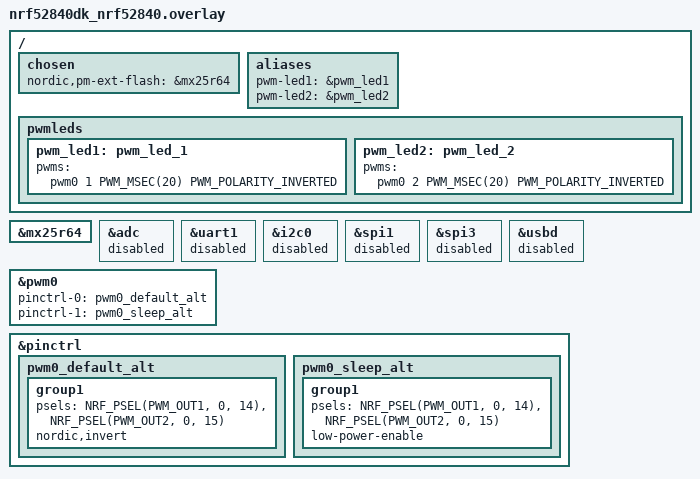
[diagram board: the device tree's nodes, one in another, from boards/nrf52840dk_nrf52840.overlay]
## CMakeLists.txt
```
#
# Copyright (c) 2022 Nordic Semiconductor ASA
#
# SPDX-License-Identifier: LicenseRef-Nordic-5-Clause
#

cmake_minimum_required(VERSION 3.20.0)

include(${CMAKE_CURRENT_LIST_DIR}/../../cmake/find_zephyr.cmake)

project(matter-window-app)

# NORDIC SDK APP START

# Include all source files that are located in the Matter common directory.
include(${ZEPHYR_NCS_MATTER_MODULE_DIR}/cmake/sample.cmake)

ncs_get_zap_parent_dir(ZAP_PARENT_DIR)

target_include_directories(app PRIVATE
  src
  ${ZAP_PARENT_DIR}
)

target_sources(app PRIVATE
  src/app_task.cpp
  src/window_covering.cpp
  src/main.cpp
  src/zcl_callbacks.cpp
)

ncs_configure_data_model()
# NORDIC SDK APP END
```

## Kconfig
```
#
# Copyright (c) 2022 Nordic Semiconductor ASA
#
# SPDX-License-Identifier: LicenseRef-Nordic-5-Clause
#

mainmenu "Matter nRF Connect Window Covering Example Application"

config STATE_LEDS
	bool "Use LEDs to indicate the device state"
	default y
	help
	  Use LEDs to render the current state of the device such as the progress of commissioning of
	  the device into a network or the factory reset initiation. Note that setting this option to
	  'n' does not disable the LED indicating the state of the simulated bolt.

# Reduce Thread TX output power to 0 dBm for SED device
config OPENTHREAD_DEFAULT_TX_POWER
	default 0

choice OPENTHREAD_IMPLEMENTATION
	default OPENTHREAD_SOURCES
endchoice

source "$(ZEPHYR_CONNECTEDHOMEIP_MODULE_DIR)/config/nrfconnect/chip-module/Kconfig.features"
source "$(ZEPHYR_CONNECTEDHOMEIP_MODULE_DIR)/config/nrfconnect/chip-module/Kconfig.defaults"
source "Kconfig.zephyr"
```

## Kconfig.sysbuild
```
#
# Copyright (c) 2023 Nordic Semiconductor ASA
#
# SPDX-License-Identifier: LicenseRef-Nordic-5-Clause
#

#### Radio core selection
config NRF_DEFAULT_IPC_RADIO
	default y

# Enable IEEE802.15.4 serialization to network core
# This config automatically pulls in the `overlay-802154.conf` in the ipc_radio image
config NETCORE_IPC_RADIO_IEEE802154
	default y if SOC_SERIES_NRF53

# Enable Bluetooth serialization to network core
# This config automatically pulls in the `overlay-bt_hci_ipc.conf` in the ipc_radio image
config NETCORE_IPC_RADIO_BT_HCI_IPC
	default y if SOC_SERIES_NRF53

#### Bootloader
choice BOOTLOADER
	default BOOTLOADER_MCUBOOT if !BOARD_NRF21540DK && !BOARD_NATIVE_SIM
endchoice

if BOOTLOADER_MCUBOOT

#### DFU multi-image support
config DFU_MULTI_IMAGE_PACKAGE_BUILD
	default y

config DFU_MULTI_IMAGE_PACKAGE_APP
	default y

#### DFU network core configuration
if SOC_SERIES_NRF53

choice MCUBOOT_MODE
	default MCUBOOT_MODE_OVERWRITE_ONLY
endchoice

choice BOOT_SIGNATURE_TYPE
	default BOOT_SIGNATURE_TYPE_RSA
endchoice

config SECURE_BOOT_NETCORE
	default y

config NETCORE_APP_UPDATE
	default y

config DFU_MULTI_IMAGE_PACKAGE_NET
	default y

endif # SOC_SERIES_NRF53
endif # BOOTLOADER_MCUBOOT

#### Enable generating factory data
config MATTER_ADD_ON_FACTORY_DATA_GENERATE
	default y if !BOARD_NRF21540DK && !BOARD_NATIVE_SIM

source "share/sysbuild/Kconfig"
```

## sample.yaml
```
sample:
  description: Matter Window Covering example
  name: Matter Window Covering
common:
  tags:
    - sysbuild
    - ci_samples_matter
tests:
  sample.matter.window_cover.debug:
    sysbuild: true
    build_only: true
    integration_platforms:
      - nrf5340dk/nrf5340/cpuapp
      - nrf54l15dk/nrf54l15/cpuapp
      - nrf54lm20dk/nrf54lm20b/cpuapp
      - nrf54lm20dk/nrf54lm20a/cpuapp
    platform_allow:
      - nrf5340dk/nrf5340/cpuapp
      - nrf54l15dk/nrf54l15/cpuapp
      - nrf54lm20dk/nrf54lm20b/cpuapp
      - nrf54lm20dk/nrf54lm20a/cpuapp
  sample.matter.window_cover.debug.ssed:
    sysbuild: true
    build_only: true
    extra_args:
      - EXTRA_CONF_FILE=ssed.conf
    integration_platforms:
      - nrf5340dk/nrf5340/cpuapp
      - nrf54l15dk/nrf54l15/cpuapp
      - nrf54lm20dk/nrf54lm20b/cpuapp
      - nrf54lm20dk/nrf54lm20a/cpuapp
    platform_allow:
      - nrf5340dk/nrf5340/cpuapp
      - nrf54l15dk/nrf54l15/cpuapp
      - nrf54lm20dk/nrf54lm20b/cpuapp
      - nrf54lm20dk/nrf54lm20a/cpuapp
  sample.matter.window_cover.release:
    sysbuild: true
    build_only: true
    extra_args:
      - FILE_SUFFIX=release
    integration_platforms:
      - nrf5340dk/nrf5340/cpuapp
      - nrf54l15dk/nrf54l15/cpuapp
      - nrf54lm20dk/nrf54lm20b/cpuapp
      - nrf54lm20dk/nrf54lm20a/cpuapp
    platform_allow:
      - nrf5340dk/nrf5340/cpuapp
      - nrf54l15dk/nrf54l15/cpuapp
      - nrf54lm20dk/nrf54lm20b/cpuapp
      - nrf54lm20dk/nrf54lm20a/cpuapp
  sample.matter.window_cover.release.ssed:
    sysbuild: true
    build_only: true
    extra_args:
      - FILE_SUFFIX=release
      - EXTRA_CONF_FILE=ssed.conf
    integration_platforms:
      - nrf5340dk/nrf5340/cpuapp
      - nrf54l15dk/nrf54l15/cpuapp
      - nrf54lm20dk/nrf54lm20b/cpuapp
      - nrf54lm20dk/nrf54lm20a/cpuapp
    platform_allow:
      - nrf5340dk/nrf5340/cpuapp
      - nrf54l15dk/nrf54l15/cpuapp
      - nrf54lm20dk/nrf54lm20b/cpuapp
      - nrf54lm20dk/nrf54lm20a/cpuapp
  sample.matter.window_cover.release.power_consumption:
    sysbuild: true
    build_only: true
    extra_args:
      - FILE_SUFFIX=release
      - CONFIG_MATTER_LEDS=n
      - CONFIG_MATTER_WATCHDOG=n
      - CONFIG_CHIP_ENABLE_PAIRING_AUTOSTART=y
    integration_platforms:
      - nrf5340dk/nrf5340/cpuapp
      - nrf54l15dk/nrf54l15/cpuapp
      - nrf54lm20dk/nrf54lm20b/cpuapp
      - nrf54lm20dk/nrf54lm20a/cpuapp
    platform_allow:
      - nrf5340dk/nrf5340/cpuapp
      - nrf54l15dk/nrf54l15/cpuapp
      - nrf54lm20dk/nrf54lm20b/cpuapp
      - nrf54lm20dk/nrf54lm20a/cpuapp
  sample.matter.window_cover.release.power_consumption.ssed:
    sysbuild: true
    build_only: true
    extra_args:
      - FILE_SUFFIX=release
      - EXTRA_CONF_FILE=ssed.conf
      - CONFIG_MATTER_LEDS=n
      - CONFIG_MATTER_WATCHDOG=n
      - CONFIG_CHIP_ENABLE_PAIRING_AUTOSTART=y
    integration_platforms:
      - nrf5340dk/nrf5340/cpuapp
      - nrf54l15dk/nrf54l15/cpuapp
      - nrf54lm20dk/nrf54lm20b/cpuapp
      - nrf54lm20dk/nrf54lm20a/cpuapp
    platform_allow:
      - nrf5340dk/nrf5340/cpuapp
      - nrf54l15dk/nrf54l15/cpuapp
      - nrf54lm20dk/nrf54lm20b/cpuapp
      - nrf54lm20dk/nrf54lm20a/cpuapp
  sample.matter.window_cover.smp_dfu:
    sysbuild: true
    build_only: true
    extra_args:
      - CONFIG_CHIP_DFU_OVER_BT_SMP=y
    integration_platforms:
      - nrf5340dk/nrf5340/cpuapp
      - nrf54lm20dk/nrf54lm20b/cpuapp
      - nrf54lm20dk/nrf54lm20a/cpuapp
    platform_allow:
      - nrf5340dk/nrf5340/cpuapp
      - nrf54l15dk/nrf54l15/cpuapp
      - nrf54lm20dk/nrf54lm20b/cpuapp
      - nrf54lm20dk/nrf54lm20a/cpuapp
```

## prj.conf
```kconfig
#
# Copyright (c) 2022 Nordic Semiconductor ASA
#
# SPDX-License-Identifier: LicenseRef-Nordic-5-Clause
#

# This sample uses Kconfig.defaults to set options common for all
# samples. This file should contain only options specific for this sample
# or overrides of default values.

# Enable CHIP
CONFIG_CHIP=y
CONFIG_CHIP_PROJECT_CONFIG="src/chip_project_config.h"
CONFIG_CHIP_DEVICE_PRODUCT_NAME="Matter Window Covering"

# Configure ZAP file name
CONFIG_MATTER_ZAP_FILE_PATH="${APPLICATION_CONFIG_DIR}/src/default_zap/window-app.zap"

# 32784 == 0x8010 (example window-app)
CONFIG_CHIP_DEVICE_PRODUCT_ID=32784
CONFIG_STD_CPP17=y

# Enable Matter pairing automatically on application start.
CONFIG_CHIP_ENABLE_PAIRING_AUTOSTART=y

# Enable Matter extended announcement and increase duration to 1 hour.
CONFIG_CHIP_BLE_EXT_ADVERTISING=y
CONFIG_CHIP_BLE_ADVERTISING_DURATION=60

# Add support for LEDs and buttons on Nordic development kits
CONFIG_DK_LIBRARY=y

# PWM support
CONFIG_PWM=y

# OpenThread configs
CONFIG_OPENTHREAD_NORDIC_LIBRARY_MTD=y
CONFIG_OPENTHREAD_MTD=y
CONFIG_OPENTHREAD_FTD=n
CONFIG_CHIP_ENABLE_ICD_SUPPORT=y
CONFIG_CHIP_ICD_SLOW_POLL_INTERVAL=1000

# Bluetooth Low Energy configuration
CONFIG_BT_DEVICE_NAME="MatterWinCov"

# Suspend devices when the CPU goes into sleep
CONFIG_PM_DEVICE=y

# Stack size settings
CONFIG_IEEE802154_NRF5_RX_STACK_SIZE=1024

# Other settings
CONFIG_THREAD_NAME=y
CONFIG_MPU_STACK_GUARD=y
CONFIG_RESET_ON_FATAL_ERROR=n
CONFIG_CHIP_LIB_SHELL=y
CONFIG_MATTER_TEST_SHELL=y

# Reduce application size
CONFIG_USE_SEGGER_RTT=n

# Enable Factory Data feature
CONFIG_CHIP_FACTORY_DATA=y
CONFIG_CHIP_FACTORY_DATA_BUILD=y
```

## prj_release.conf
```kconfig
#
# Copyright (c) 2022 Nordic Semiconductor ASA
#
# SPDX-License-Identifier: LicenseRef-Nordic-5-Clause
#

# This sample uses Kconfig.defaults to set options common for all
# samples. This file should contain only options specific for this sample
# or overrides of default values.

# Enable CHIP
CONFIG_CHIP=y
CONFIG_CHIP_PROJECT_CONFIG="src/chip_project_config.h"
CONFIG_CHIP_DEVICE_PRODUCT_NAME="Matter Window Covering"

# Configure ZAP file name
CONFIG_MATTER_ZAP_FILE_PATH="${APPLICATION_CONFIG_DIR}/src/default_zap/window-app.zap"

# 32784 == 0x8010 (example window-app)
CONFIG_CHIP_DEVICE_PRODUCT_ID=32784
CONFIG_STD_CPP17=y

# Enable Matter pairing automatically on application start.
CONFIG_CHIP_ENABLE_PAIRING_AUTOSTART=y

# Enable Matter extended announcement and increase duration to 1 hour.
CONFIG_CHIP_BLE_EXT_ADVERTISING=y
CONFIG_CHIP_BLE_ADVERTISING_DURATION=60

# Add support for LEDs and buttons on Nordic development kits
CONFIG_DK_LIBRARY=y

# Try to disable unused RAM blocks to reduce power consumption
CONFIG_RAM_POWER_DOWN_LIBRARY=y

# PWM support
CONFIG_PWM=y

# OpenThread configs
CONFIG_OPENTHREAD_NORDIC_LIBRARY_MTD=y
CONFIG_OPENTHREAD_MTD=y
CONFIG_OPENTHREAD_FTD=n
CONFIG_CHIP_ENABLE_ICD_SUPPORT=y
CONFIG_CHIP_ICD_SLOW_POLL_INTERVAL=1000

# Bluetooth Low Energy configuration
CONFIG_BT_DEVICE_NAME="MatterWinCov"

# Suspend devices when the CPU goes into sleep
CONFIG_PM_DEVICE=y

# Stack size settings
CONFIG_IEEE802154_NRF5_RX_STACK_SIZE=1024

# Enable system reset on fatal error
CONFIG_RESET_ON_FATAL_ERROR=y

# Disable all debug features
CONFIG_USE_SEGGER_RTT=n
CONFIG_SHELL=n
CONFIG_OPENTHREAD_SHELL=n
CONFIG_CONSOLE=n
CONFIG_UART_CONSOLE=n
CONFIG_SERIAL=n
CONFIG_LOG=n
CONFIG_LOG_MODE_MINIMAL=n
CONFIG_ASSERT_VERBOSE=n
CONFIG_ASSERT_NO_FILE_INFO=y
CONFIG_PRINTK=n
CONFIG_PRINTK_SYNC=n
CONFIG_THREAD_NAME=n
CONFIG_BOOT_BANNER=n

# Enable Factory Data feature
CONFIG_CHIP_FACTORY_DATA=y
CONFIG_CHIP_FACTORY_DATA_BUILD=y

# Enable Watchdog
CONFIG_MATTER_WATCHDOG=y

# Enable LTO to decrease the flash usage.
CONFIG_LTO=y
CONFIG_ISR_TABLES_LOCAL_DECLARATION=y
```

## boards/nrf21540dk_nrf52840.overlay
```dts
/* Copyright (c) 2021 Nordic Semiconductor ASA
 *
 * SPDX-License-Identifier: LicenseRef-Nordic-5-Clause
 */

#include <nrf52840_partitions.dtsi>

/ {
	/*
	 * Configure LED2 and LED3 to show the state of the
	 * window cover,by using the LED's brightness level.
	 */
	aliases {
		pwm-led1 = &pwm_led1;
		pwm-led2 = &pwm_led2;
	};

	pwmleds {
		pwm_led1: pwm_led_1 {
			pwms = <&pwm0 1 PWM_MSEC(20) PWM_POLARITY_INVERTED>;
		};

		pwm_led2: pwm_led_2 {
			pwms = <&pwm0 2 PWM_MSEC(20) PWM_POLARITY_INVERTED>;
		};
	};
};

/* Disable unused peripherals to reduce power consumption */
&adc {
	status = "disabled";
};

&uart1 {
	status = "disabled";
};

&i2c0 {
	status = "disabled";
};

&spi1 {
	status = "disabled";
};

&spi3 {
	status = "disabled";
};

&usbd {
	status = "disabled";
};

&pwm0 {
	pinctrl-0 = <&pwm0_default_alt>;
	pinctrl-1 = <&pwm0_sleep_alt>;
	pinctrl-names = "default", "sleep";
};

&pinctrl {
	pwm0_default_alt: pwm0_default_alt {
		group1 {
			psels = <NRF_PSEL(PWM_OUT1, 0, 14)>, <NRF_PSEL(PWM_OUT2, 0, 15)>;
			nordic,invert;
		};
	};

	pwm0_sleep_alt: pwm0_sleep_alt {
		group1 {
			psels = <NRF_PSEL(PWM_OUT1, 0, 14)>, <NRF_PSEL(PWM_OUT2, 0, 15)>;
			low-power-enable;
		};
	};
};
```

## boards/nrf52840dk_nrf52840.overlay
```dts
/*
 * Copyright (c) 2021 Nordic Semiconductor ASA
 *
 * SPDX-License-Identifier: LicenseRef-Nordic-5-Clause
 */

#include <nrf52840_partitions.dtsi>

/ {
	chosen {
		nordic,pm-ext-flash = &mx25r64;
	};

	/*
	 * Configure LED2 and LED3 to show the state of the
	 * window cover,by using the LED's brightness level.
	 */
	aliases {
		pwm-led1 = &pwm_led1;
		pwm-led2 = &pwm_led2;
	};

	pwmleds {
		pwm_led1: pwm_led_1 {
			pwms = <&pwm0 1 PWM_MSEC(20) PWM_POLARITY_INVERTED>;
		};

		pwm_led2: pwm_led_2 {
			pwms = <&pwm0 2 PWM_MSEC(20) PWM_POLARITY_INVERTED>;
		};
	};
};

&mx25r64 {
	status = "okay";
};

/* Disable unused peripherals to reduce power consumption */
&adc {
	status = "disabled";
};

&uart1 {
	status = "disabled";
};

&i2c0 {
	status = "disabled";
};

&spi1 {
	status = "disabled";
};

&spi3 {
	status = "disabled";
};

&usbd {
	status = "disabled";
};

&pwm0 {
	pinctrl-0 = <&pwm0_default_alt>;
	pinctrl-1 = <&pwm0_sleep_alt>;
	pinctrl-names = "default", "sleep";
};

&pinctrl {
	pwm0_default_alt: pwm0_default_alt {
		group1 {
			psels = <NRF_PSEL(PWM_OUT1, 0, 14)>, <NRF_PSEL(PWM_OUT2, 0, 15)>;
			nordic,invert;
		};
	};

	pwm0_sleep_alt: pwm0_sleep_alt {
		group1 {
			psels = <NRF_PSEL(PWM_OUT1, 0, 14)>, <NRF_PSEL(PWM_OUT2, 0, 15)>;
			low-power-enable;
		};
	};
};
```

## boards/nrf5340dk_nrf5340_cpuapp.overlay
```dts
/*
 * Copyright (c) 2021 Nordic Semiconductor ASA
 *
 * SPDX-License-Identifier: LicenseRef-Nordic-5-Clause
 */

#include <nrf5340_cpuapp_partitions.dtsi>
#include <zephyr/dt-bindings/ipc_service/static_vrings.h>

/ {
	chosen {
		nordic,pm-ext-flash = &mx25r64;
	};

	/*
	 * Configure LED2 and LED3 to show the state of the
	 * window cover,by using the LED's brightness level.
	 */
	aliases {
		pwm-led1 = &pwm_led1;
		pwm-led2 = &pwm_led2;
	};

	pwmleds {
		compatible = "pwm-leds";

		pwm_led1: pwm_led_1 {
			pwms = <&pwm0 1 PWM_MSEC(20) PWM_POLARITY_INVERTED>;
		};

		pwm_led2: pwm_led_2 {
			pwms = <&pwm0 2 PWM_MSEC(20) PWM_POLARITY_INVERTED>;
		};
	};
};

&mx25r64 {
	status = "okay";
};

/* Set IPC thread priority to the highest value to not collide with other threads. */
&ipc0 {
	zephyr,priority = <0 PRIO_COOP>;
};

/* Disable unused peripherals to reduce power consumption */
&adc {
	status = "disabled";
};

&i2c1 {
	status = "disabled";
};

&spi2 {
	status = "disabled";
};

&usbd {
	status = "disabled";
};

&pwm0 {
	pinctrl-0 = <&pwm0_default_alt>;
	pinctrl-1 = <&pwm0_sleep_alt>;
	pinctrl-names = "default", "sleep";
};

&pinctrl {
	pwm0_default_alt: pwm0_default_alt {
		group1 {
			psels = <NRF_PSEL(PWM_OUT1, 0, 29)>, <NRF_PSEL(PWM_OUT2, 0, 30)>;
			nordic,invert;
		};
	};

	pwm0_sleep_alt: pwm0_sleep_alt {
		group1 {
			psels = <NRF_PSEL(PWM_OUT1, 0, 29)>, <NRF_PSEL(PWM_OUT2, 0, 30)>;
			low-power-enable;
		};
	};
};
```

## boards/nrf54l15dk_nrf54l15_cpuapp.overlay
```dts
/*
 * Copyright (c) 2024 Nordic Semiconductor ASA
 *
 * SPDX-License-Identifier: LicenseRef-Nordic-5-Clause
 */

#include <nrf54l15_cpuapp_partitions.dtsi>

/ {
	chosen {
		nordic,pm-ext-flash = &mx25r64;
	};

	aliases {
		/* Configure PWM module for led1 (LED2 on the board) */
		pwm-led1 = &pwm_led1;
		pwm-led2 = &pwm_led2;

		/* Use watchdog wdt31 as the application watchdog */
		watchdog0 = &wdt31;
	};

	pwmleds {
		compatible = "pwm-leds";

		pwm_led1: pwm_led_1 {
			pwms = <&pwm20 1 PWM_MSEC(20) PWM_POLARITY_NORMAL>;
		};

		pwm_led2: pwm_led_2 {
			pwms = <&pwm20 2 PWM_MSEC(20) PWM_POLARITY_NORMAL>;
		};
	};
};

&mx25r64 {
	status = "okay";
};

&pwm20 {
	status = "okay";
	pinctrl-0 = <&pwm_default>;
	pinctrl-1 = <&pwm_sleep>;
	pinctrl-names = "default", "sleep";
};

&pinctrl {
	pwm_default: pwm_default {
		group1 {
			psels = <NRF_PSEL(PWM_OUT1, 1, 10)>, <NRF_PSEL(PWM_OUT2, 1, 14)>;
		};
	};

	pwm_sleep: pwm_sleep {
		group1 {
			psels = <NRF_PSEL(PWM_OUT1, 1, 10)>, <NRF_PSEL(PWM_OUT2, 1, 14)>;
			low-power-enable;
		};
	};
};

&wdt31 {
	status = "okay";
};
```

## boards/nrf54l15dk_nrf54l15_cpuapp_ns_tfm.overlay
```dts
/*
 * Copyright (c) 2026 Nordic Semiconductor ASA
 *
 * SPDX-License-Identifier: LicenseRef-Nordic-5-Clause
 */

#include <nrf54l15_cpuapp_tfm_application_partitions.dtsi>

/ {
	chosen {
		nordic,pm-ext-flash = &mx25r64;
	};

	aliases {
		/* Configure PWM module for led1 (LED2 on the board) */
		pwm-led1 = &pwm_led1;
		pwm-led2 = &pwm_led2;

		/* Use watchdog wdt31 as the application watchdog */
		watchdog0 = &wdt31;
	};

	pwmleds {
		compatible = "pwm-leds";

		pwm_led1: pwm_led_1 {
			pwms = <&pwm20 1 PWM_MSEC(20) PWM_POLARITY_NORMAL>;
		};

		pwm_led2: pwm_led_2 {
			pwms = <&pwm20 2 PWM_MSEC(20) PWM_POLARITY_NORMAL>;
		};
	};
};

&mx25r64 {
	status = "okay";
};

&pwm20 {
	status = "okay";
	pinctrl-0 = <&pwm_default>;
	pinctrl-1 = <&pwm_sleep>;
	pinctrl-names = "default", "sleep";
};

&pinctrl {
	pwm_default: pwm_default {
		group1 {
			psels = <NRF_PSEL(PWM_OUT1, 1, 10)>, <NRF_PSEL(PWM_OUT2, 1, 14)>;
		};
	};

	pwm_sleep: pwm_sleep {
		group1 {
			psels = <NRF_PSEL(PWM_OUT1, 1, 10)>, <NRF_PSEL(PWM_OUT2, 1, 14)>;
			low-power-enable;
		};
	};
};

&wdt31 {
	status = "okay";
};

/* Change IRQ ids to handle button interrupts.
 * The default values for nRF54L15 are 219 and 269,
 * but with TF-M they are reserved for the secure domain
 * (218 and 268 are reserved for the non-secure domain).
 */
&gpiote20 {
	interrupts = <218 NRF_DEFAULT_IRQ_PRIORITY>;
};

&gpiote30 {
	interrupts = <268 NRF_DEFAULT_IRQ_PRIORITY>;
};
```

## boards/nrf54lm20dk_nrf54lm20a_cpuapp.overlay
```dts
/*
 * Copyright (c) 2025 Nordic Semiconductor ASA
 *
 * SPDX-License-Identifier: LicenseRef-Nordic-5-Clause
 */

#include <nrf54lm20_cpuapp_partitions.dtsi>

/ {
	chosen {
		nordic,pm-ext-flash = &mx25r64;
	};

	aliases {
		pwm-led1 = &pwm_led1;
		pwm-led2 = &pwm_led2;

		/* Use watchdog wdt31 as the application watchdog */
		watchdog0 = &wdt31;
	};

	pwmleds {
		compatible = "pwm-leds";

		pwm_led1: pwm_led_1 {
			pwms = <&pwm20 1 PWM_MSEC(20) PWM_POLARITY_NORMAL>;
		};

		pwm_led2: pwm_led_2 {
			pwms = <&pwm20 2 PWM_MSEC(20) PWM_POLARITY_NORMAL>;
		};
	};
};

&pwm20 {
	status = "okay";
	pinctrl-0 = <&pwm_default>;
	pinctrl-1 = <&pwm_sleep>;
	pinctrl-names = "default", "sleep";
};

&pinctrl {
	pwm_default: pwm_default {
		group1 {
			psels = <NRF_PSEL(PWM_OUT1, 1, 25)>, <NRF_PSEL(PWM_OUT2, 1, 27)>;
		};
	};

	pwm_sleep: pwm_sleep {
		group1 {
			psels = <NRF_PSEL(PWM_OUT1, 1, 25)>, <NRF_PSEL(PWM_OUT2, 1, 27)>;
			low-power-enable;
		};
	};
};

&mx25r64 {
	status = "okay";
};

&wdt31 {
	status = "okay";
};
```

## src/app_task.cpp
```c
/*
 * Copyright (c) 2022 Nordic Semiconductor ASA
 *
 * SPDX-License-Identifier: LicenseRef-Nordic-5-Clause
 */

#include "app_task.h"

#include "window_covering.h"

#include "app/matter_init.h"
#include "app/task_executor.h"
#include "clusters/identify.h"

#include <setup_payload/OnboardingCodesUtil.h>

#include <zephyr/logging/log.h>

LOG_MODULE_DECLARE(app, CONFIG_CHIP_APP_LOG_LEVEL);

using namespace ::chip;
using namespace ::chip::app;
using namespace ::chip::DeviceLayer;

namespace
{
Nrf::Matter::IdentifyCluster sIdentifyCluster(WindowCovering::Endpoint());

#ifdef CONFIG_DK_LIBRARY
#define OPEN_BUTTON_MASK DK_BTN2_MSK
#define CLOSE_BUTTON_MASK DK_BTN3_MSK
#else
#define OPEN_BUTTON_MASK 0
#define CLOSE_BUTTON_MASK 0
#endif
} /* namespace */

void AppTask::ButtonEventHandler(Nrf::ButtonState state, Nrf::ButtonMask hasChanged)
{
	if (OPEN_BUTTON_MASK & hasChanged) {
		WindowButtonAction action =
			(OPEN_BUTTON_MASK & state) ? WindowButtonAction::Pressed : WindowButtonAction::Released;
		Nrf::PostTask([action] { OpenHandler(action); });
	}

	if (CLOSE_BUTTON_MASK & hasChanged) {
		WindowButtonAction action =
			(CLOSE_BUTTON_MASK & state) ? WindowButtonAction::Pressed : WindowButtonAction::Released;
		Nrf::PostTask([action] { CloseHandler(action); });
	}
}

void AppTask::OpenHandler(const WindowButtonAction &action)
{
	if (action == WindowButtonAction::Pressed) {
		Instance().mOpenButtonIsPressed = true;
		if (Instance().mCloseButtonIsPressed) {
			Instance().ToggleMoveType();
		}
	} else {
		if (!Instance().mCloseButtonIsPressed) {
			if (!Instance().mMoveTypeRecentlyChanged) {
				WindowCovering::Instance().SetSingleStepTarget(OperationalState::MovingUpOrOpen);
			} else {
				Instance().mMoveTypeRecentlyChanged = false;
			}
		}
		Instance().mOpenButtonIsPressed = false;
	}
}

void AppTask::CloseHandler(const WindowButtonAction &action)
{
	if (action == WindowButtonAction::Pressed) {
		Instance().mCloseButtonIsPressed = true;
		if (Instance().mOpenButtonIsPressed) {
			Instance().ToggleMoveType();
		}
	} else {
		if (!Instance().mOpenButtonIsPressed) {
			if (!Instance().mMoveTypeRecentlyChanged) {
				WindowCovering::Instance().SetSingleStepTarget(OperationalState::MovingDownOrClose);
			} else {
				Instance().mMoveTypeRecentlyChanged = false;
			}
		}
		Instance().mCloseButtonIsPressed = false;
	}
}

void AppTask::ToggleMoveType()
{
	if (WindowCovering::Instance().GetMoveType() == WindowCovering::MoveType::LIFT) {
		WindowCovering::Instance().SetMoveType(WindowCovering::MoveType::TILT);
		LOG_INF("Window covering move: tilt");
	} else {
		WindowCovering::Instance().SetMoveType(WindowCovering::MoveType::LIFT);
		LOG_INF("Window covering move: lift");
	}
	mMoveTypeRecentlyChanged = true;
}

CHIP_ERROR AppTask::Init()
{
	/* Initialize Matter stack */
	ReturnErrorOnFailure(Nrf::Matter::PrepareServer(Nrf::Matter::InitData{ .mPostServerInitClbk = [] {
		WindowCovering::Instance().PositionLEDUpdate(WindowCovering::MoveType::LIFT);
		WindowCovering::Instance().PositionLEDUpdate(WindowCovering::MoveType::TILT);
		return CHIP_NO_ERROR;
	} }));

	if (!Nrf::GetBoard().Init(ButtonEventHandler)) {
		LOG_ERR("User interface initialization failed.");
		return CHIP_ERROR_INCORRECT_STATE;
	}

	/* Register Matter event handler that controls the connectivity status LED based on the captured Matter network
	 * state. */
	ReturnErrorOnFailure(Nrf::Matter::RegisterEventHandler(Nrf::Board::DefaultMatterEventHandler, 0));

	return Nrf::Matter::StartServer();
}

CHIP_ERROR AppTask::StartApp()
{
	ReturnErrorOnFailure(Init());

	while (true) {
		Nrf::DispatchNextTask();
	}

	return CHIP_NO_ERROR;
}
```

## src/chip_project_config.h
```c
/*
 * Copyright (c) 2022 Nordic Semiconductor ASA
 *
 * SPDX-License-Identifier: LicenseRef-Nordic-5-Clause
 */

/**
 *    @file
 *          Example project configuration file for CHIP.
 *
 *          This is a place to put application or project-specific overrides
 *          to the default configuration values for general CHIP features.
 *
 */

#pragma once

#include "../../../subsys/app/chip_project_config_native_sim.h"
```

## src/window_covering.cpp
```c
/*
 * Copyright (c) 2022 Nordic Semiconductor ASA
 *
 * SPDX-License-Identifier: LicenseRef-Nordic-5-Clause
 */

#include "window_covering.h"

#if defined(CONFIG_PWM)
#include "pwm/pwm_device.h"
#endif

#include <app-common/zap-generated/attributes/Accessors.h>
#include <lib/support/logging/CHIPLogging.h>
#include <platform/CHIPDeviceLayer.h>
#include <zephyr/kernel.h>
#include <zephyr/logging/log.h>

LOG_MODULE_DECLARE(app, CONFIG_CHIP_APP_LOG_LEVEL);

using namespace ::chip;
using namespace ::chip::DeviceLayer;
using namespace chip::app::Clusters::WindowCovering;

#if defined(CONFIG_PWM)
static const struct pwm_dt_spec sLiftPwmDevice = PWM_DT_SPEC_GET(DT_ALIAS(pwm_led1));
static const struct pwm_dt_spec sTiltPwmDevice = PWM_DT_SPEC_GET(DT_ALIAS(pwm_led2));
#endif

static constexpr uint32_t sMoveTimeoutMs{ 200 };

WindowCovering::WindowCovering()
{
#if defined(CONFIG_PWM)
	if (mLiftIndicator.Init(&sLiftPwmDevice, 0, 255) != 0) {
		LOG_ERR("Cannot initialize the lift indicator");
	}
	if (mTiltIndicator.Init(&sTiltPwmDevice, 0, 255) != 0) {
		LOG_ERR("Cannot initialize the tilt indicator");
	}
#endif
}

void WindowCovering::DriveCurrentLiftPosition(intptr_t)
{
	NPercent100ths current{};
	NPercent100ths target{};
	NPercent100ths positionToSet{};

	VerifyOrReturn(Attributes::CurrentPositionLiftPercent100ths::Get(Endpoint(), current) ==
		       Protocols::InteractionModel::Status::Success);
	VerifyOrReturn(Attributes::TargetPositionLiftPercent100ths::Get(Endpoint(), target) ==
		       Protocols::InteractionModel::Status::Success);

	OperationalState state = ComputeOperationalState(target, current);
	UpdateOperationalStatus(MoveType::LIFT, state);

	chip::Percent100ths position = CalculateNextPosition(MoveType::LIFT);

	if (state == OperationalState::MovingUpOrOpen) {
		positionToSet.SetNonNull(position > target.Value() ? position : target.Value());
	} else if (state == OperationalState::MovingDownOrClose) {
		positionToSet.SetNonNull(position < target.Value() ? position : target.Value());
	} else {
		positionToSet.SetNonNull(current.Value());
	}

	LiftPositionSet(Endpoint(), positionToSet);

	/* assume single move completed */
	Instance().mInLiftMove = false;

	VerifyOrReturn(Attributes::CurrentPositionLiftPercent100ths::Get(Endpoint(), current) ==
		       Protocols::InteractionModel::Status::Success);

	if (!TargetCompleted(MoveType::LIFT, current, target)) {
		/* continue to move */
		StartTimer(MoveType::LIFT, sMoveTimeoutMs);
	} else {
		/* the OperationalStatus should indicate no-lift-movement after the target is completed */
		UpdateOperationalStatus(MoveType::LIFT, ComputeOperationalState(target, current));
	}
}

chip::Percent100ths WindowCovering::CalculateNextPosition(MoveType aMoveType)
{
	Protocols::InteractionModel::Status status{};
	chip::Percent100ths percent100ths{};
	NPercent100ths current{};
	OperationalState opState{};

	if (aMoveType == MoveType::LIFT) {
		status = Attributes::CurrentPositionLiftPercent100ths::Get(Endpoint(), current);
		opState = OperationalStateGet(Endpoint(), OperationalStatus::kLift);
	} else if (aMoveType == MoveType::TILT) {
		status = Attributes::CurrentPositionTiltPercent100ths::Get(Endpoint(), current);
		opState = OperationalStateGet(Endpoint(), OperationalStatus::kTilt);
	}

	if ((status == Protocols::InteractionModel::Status::Success) && !current.IsNull()) {
		static constexpr auto sPercentDelta{ WC_PERCENT100THS_MAX_CLOSED / 20 };
		percent100ths = ComputePercent100thsStep(opState, current.Value(), sPercentDelta);
	} else {
		LOG_ERR("Cannot read the current lift position. Error: %d", static_cast<uint8_t>(status));
	}

	return percent100ths;
}

bool WindowCovering::TargetCompleted(MoveType aMoveType, NPercent100ths aCurrent, NPercent100ths aTarget)
{
	return (OperationalState::Stall == ComputeOperationalState(aTarget, aCurrent));
}

void WindowCovering::StartTimer(MoveType aMoveType, uint32_t aTimeoutMs)
{
	MoveType *moveType = chip::Platform::New<MoveType>();
	VerifyOrReturn(moveType != nullptr);

	*moveType = aMoveType;
	(void)chip::DeviceLayer::SystemLayer().StartTimer(chip::System::Clock::Milliseconds32(aTimeoutMs),
							  MoveTimerTimeoutCallback, reinterpret_cast<void *>(moveType));
}

void WindowCovering::MoveTimerTimeoutCallback(chip::System::Layer *systemLayer, void *appState)
{
	MoveType *moveType = reinterpret_cast<MoveType *>(appState);
	VerifyOrReturn(moveType != nullptr);

	if (*moveType == MoveType::LIFT) {
		CHIP_ERROR err = chip::DeviceLayer::PlatformMgr().ScheduleWork(WindowCovering::DriveCurrentLiftPosition);
		if (err != CHIP_NO_ERROR) {
			ChipLogError(NotSpecified, "ScheduleWork failed: %" CHIP_ERROR_FORMAT, err.Format());
		}
	} else if (*moveType == MoveType::TILT) {
		CHIP_ERROR err = chip::DeviceLayer::PlatformMgr().ScheduleWork(WindowCovering::DriveCurrentTiltPosition);
		if (err != CHIP_NO_ERROR) {
			ChipLogError(NotSpecified, "ScheduleWork failed: %" CHIP_ERROR_FORMAT, err.Format());
		}
	}

	chip::Platform::Delete(moveType);
}

void WindowCovering::DriveCurrentTiltPosition(intptr_t)
{
	NPercent100ths current{};
	NPercent100ths target{};
	NPercent100ths positionToSet{};

	VerifyOrReturn(Attributes::CurrentPositionTiltPercent100ths::Get(Endpoint(), current) ==
		       Protocols::InteractionModel::Status::Success);
	VerifyOrReturn(Attributes::TargetPositionTiltPercent100ths::Get(Endpoint(), target) ==
		       Protocols::InteractionModel::Status::Success);

	OperationalState state = ComputeOperationalState(target, current);
	UpdateOperationalStatus(MoveType::TILT, state);

	chip::Percent100ths position = CalculateNextPosition(MoveType::TILT);

	if (state == OperationalState::MovingUpOrOpen) {
		positionToSet.SetNonNull(position > target.Value() ? position : target.Value());
	} else if (state == OperationalState::MovingDownOrClose) {
		positionToSet.SetNonNull(position < target.Value() ? position : target.Value());
	} else {
		positionToSet.SetNonNull(current.Value());
	}

	TiltPositionSet(Endpoint(), positionToSet);

	/* assume single move completed */
	Instance().mInTiltMove = false;

	VerifyOrReturn(Attributes::CurrentPositionTiltPercent100ths::Get(Endpoint(), current) ==
		       Protocols::InteractionModel::Status::Success);

	if (!TargetCompleted(MoveType::TILT, current, target)) {
		/* continue to move */
		StartTimer(MoveType::TILT, sMoveTimeoutMs);
	} else {
		/* the OperationalStatus should indicate no-tilt-movement after the target is completed */
		UpdateOperationalStatus(MoveType::TILT, ComputeOperationalState(target, current));
	}
}

void WindowCovering::StartMove(MoveType aMoveType)
{
	switch (aMoveType) {
	case MoveType::LIFT:
		if (!mInLiftMove) {
			mInLiftMove = true;
			StartTimer(aMoveType, sMoveTimeoutMs);
		}
		break;
	case MoveType::TILT:
		if (!mInTiltMove) {
			mInTiltMove = true;
			StartTimer(aMoveType, sMoveTimeoutMs);
		}
		break;
	default:
		break;
	};
}

void WindowCovering::SetSingleStepTarget(OperationalState aDirection)
{
	UpdateOperationalStatus(mCurrentUIMoveType, aDirection);
	SetTargetPosition(aDirection, CalculateNextPosition(mCurrentUIMoveType));
}

void WindowCovering::UpdateOperationalStatus(MoveType aMoveType, OperationalState aDirection)
{
	switch (aMoveType) {
	case MoveType::LIFT:
		OperationalStateSet(Endpoint(), OperationalStatus::kLift, aDirection);
		break;
	case MoveType::TILT:
		OperationalStateSet(Endpoint(), OperationalStatus::kTilt, aDirection);
		break;
	case MoveType::NONE:
		break;
	default:
		break;
	}
}

void WindowCovering::SetTargetPosition(OperationalState aDirection, chip::Percent100ths aPosition)
{
	Protocols::InteractionModel::Status status{};
	if (Instance().mCurrentUIMoveType == MoveType::LIFT) {
		status = Attributes::TargetPositionLiftPercent100ths::Set(Endpoint(), aPosition);
	} else if (Instance().mCurrentUIMoveType == MoveType::TILT) {
		status = Attributes::TargetPositionTiltPercent100ths::Set(Endpoint(), aPosition);
	}

	if (status != Protocols::InteractionModel::Status::Success) {
		LOG_ERR("Cannot set the target position. Error: %d", static_cast<uint8_t>(status));
	}
}

void WindowCovering::PositionLEDUpdate(MoveType aMoveType)
{
	Protocols::InteractionModel::Status status{};
	NPercent100ths currentPosition{};

	if (aMoveType == MoveType::LIFT) {
		status = Attributes::CurrentPositionLiftPercent100ths::Get(Endpoint(), currentPosition);
		if (Protocols::InteractionModel::Status::Success == status && !currentPosition.IsNull()) {
			Instance().SetBrightness(MoveType::LIFT, currentPosition.Value());
		}
	} else if (aMoveType == MoveType::TILT) {
		status = Attributes::CurrentPositionTiltPercent100ths::Get(Endpoint(), currentPosition);
		if (Protocols::InteractionModel::Status::Success == status && !currentPosition.IsNull()) {
			Instance().SetBrightness(MoveType::TILT, currentPosition.Value());
		}
	}
}

void WindowCovering::SetBrightness(MoveType aMoveType, uint16_t aPosition)
{
#if defined(CONFIG_PWM)
	uint8_t brightness = PositionToBrightness(aPosition, aMoveType);
	if (aMoveType == MoveType::LIFT) {
		mLiftIndicator.InitiateAction(Nrf::PWMDevice::LEVEL_ACTION, 0, &brightness);
	} else if (aMoveType == MoveType::TILT) {
		mTiltIndicator.InitiateAction(Nrf::PWMDevice::LEVEL_ACTION, 0, &brightness);
	}
#else
	ARG_UNUSED(aMoveType);
	ARG_UNUSED(aPosition);
#endif
}

uint8_t WindowCovering::PositionToBrightness(uint16_t aPosition, MoveType aMoveType)
{
#if defined(CONFIG_PWM)
	AbsoluteLimits pwmLimits{};

	if (aMoveType == MoveType::LIFT) {
		pwmLimits.open = mLiftIndicator.GetMinLevel();
		pwmLimits.closed = mLiftIndicator.GetMaxLevel();
	} else if (aMoveType == MoveType::TILT) {
		pwmLimits.open = mTiltIndicator.GetMinLevel();
		pwmLimits.closed = mTiltIndicator.GetMaxLevel();
	}

	return Percent100thsToValue(pwmLimits, aPosition);
#else
	ARG_UNUSED(aPosition);
	ARG_UNUSED(aMoveType);
	return 0;
#endif
}

void WindowCovering::SchedulePostAttributeChange(chip::EndpointId aEndpoint, chip::AttributeId aAttributeId)
{
	AttributeUpdateData *data = chip::Platform::New<AttributeUpdateData>();
	VerifyOrReturn(data != nullptr);

	data->mEndpoint = aEndpoint;
	data->mAttributeId = aAttributeId;

	CHIP_ERROR err =
		chip::DeviceLayer::PlatformMgr().ScheduleWork(DoPostAttributeChange, reinterpret_cast<intptr_t>(data));
	if (err != CHIP_NO_ERROR) {
		chip::Platform::Delete(data);
		ChipLogError(NotSpecified, "ScheduleWork failed: %" CHIP_ERROR_FORMAT, err.Format());
	}
}

void WindowCovering::DoPostAttributeChange(intptr_t aArg)
{
	AttributeUpdateData *data = reinterpret_cast<AttributeUpdateData *>(aArg);
	VerifyOrReturn(data != nullptr);

	PostAttributeChange(data->mEndpoint, data->mAttributeId);

	chip::Platform::Delete(data);
}
```

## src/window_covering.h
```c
/*
 * Copyright (c) 2022 Nordic Semiconductor ASA
 *
 * SPDX-License-Identifier: LicenseRef-Nordic-5-Clause
 */

#pragma once

#include "board/board.h"
#include "pwm/pwm_device.h"

#include <app/clusters/window-covering-server/window-covering-server.h>

#include <cstdint>

using namespace chip::app::Clusters::WindowCovering;

class WindowCovering {
public:
	enum class MoveType : uint8_t { LIFT = 0, TILT, NONE };

	struct AttributeUpdateData {
		chip::EndpointId mEndpoint;
		chip::AttributeId mAttributeId;
	};

	WindowCovering();
	static WindowCovering &Instance()
	{
		static WindowCovering sInstance;
		return sInstance;
	}

	Nrf::PWMDevice &GetLiftIndicator() { return mLiftIndicator; }
	Nrf::PWMDevice &GetTiltIndicator() { return mTiltIndicator; }

	void StartMove(MoveType aMoveType);
	void SetSingleStepTarget(OperationalState aDirection);
	void SetMoveType(MoveType aMoveType) { mCurrentUIMoveType = aMoveType; }
	MoveType GetMoveType() { return mCurrentUIMoveType; }
	void PositionLEDUpdate(MoveType aMoveType);

	static void SchedulePostAttributeChange(chip::EndpointId aEndpoint, chip::AttributeId aAttributeId);
	static constexpr chip::EndpointId Endpoint() { return 1; };

private:
	void SetBrightness(MoveType aMoveType, uint16_t aPosition);
	void SetTargetPosition(OperationalState aDirection, chip::Percent100ths aPosition);
	uint8_t PositionToBrightness(uint16_t aPosition, MoveType aMoveType);

	static void UpdateOperationalStatus(MoveType aMoveType, OperationalState aDirection);
	static bool TargetCompleted(MoveType aMoveType, NPercent100ths aCurrent, NPercent100ths aTarget);
	static void StartTimer(MoveType aMoveType, uint32_t aTimeoutMs);
	static chip::Percent100ths CalculateNextPosition(MoveType aMoveType);
	static void DriveCurrentLiftPosition(intptr_t);
	static void DriveCurrentTiltPosition(intptr_t);
	static void MoveTimerTimeoutCallback(chip::System::Layer *systemLayer, void *appState);
	static void DoPostAttributeChange(intptr_t aArg);

	MoveType mCurrentUIMoveType;
	Nrf::PWMDevice mLiftIndicator;
	Nrf::PWMDevice mTiltIndicator;
	bool mInLiftMove{ false };
	bool mInTiltMove{ false };
};
```
